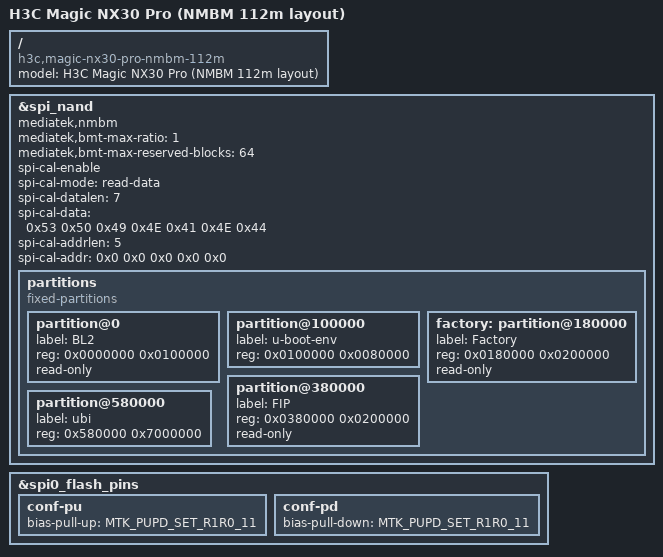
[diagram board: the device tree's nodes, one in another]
// SPDX-License-Identifier: GPL-2.0-or-later OR MIT

/dts-v1/;
#include "mt7981b-h3c-magic-nx30-pro.dts"

/ {
	model = "H3C Magic NX30 Pro (NMBM 112m layout)";
	compatible = "h3c,magic-nx30-pro-nmbm-112m", "mediatek,mt7981";
};

&spi_nand {
	mediatek,nmbm;
	mediatek,bmt-max-ratio = <1>;
	mediatek,bmt-max-reserved-blocks = <64>;

	spi-cal-enable;
	spi-cal-mode = "read-data";
	spi-cal-datalen = <7>;
	spi-cal-data = /bits/ 8 <0x53 0x50 0x49 0x4E 0x41 0x4E 0x44>;
	spi-cal-addrlen = <5>;
	spi-cal-addr = /bits/ 32 <0x0 0x0 0x0 0x0 0x0>;
	
	partitions {
		compatible = "fixed-partitions";
		#address-cells = <1>;
		#size-cells = <1>;

		partition@0 {
			label = "BL2";
			reg = <0x0000000 0x0100000>;
			read-only;
		};

		partition@100000 {
			label = "u-boot-env";
			reg = <0x0100000 0x0080000>;
		};

		factory: partition@180000 {
			label = "Factory";
			reg = <0x0180000 0x0200000>;
			read-only;
		};

		partition@380000 {
			label = "FIP";
			reg = <0x0380000 0x0200000>;
			read-only;
		};

		partition@580000 {
			label = "ubi";
			reg = <0x580000 0x7000000>;
		};

	};
};

&spi0_flash_pins {
	conf-pu {
		/delete-property/ mediatek,pull-up-adv;
		bias-pull-up = <MTK_PUPD_SET_R1R0_11>;
	};

	conf-pd {
		/delete-property/ mediatek,pull-up-adv;
		bias-pull-down = <MTK_PUPD_SET_R1R0_11>;
	};
};
